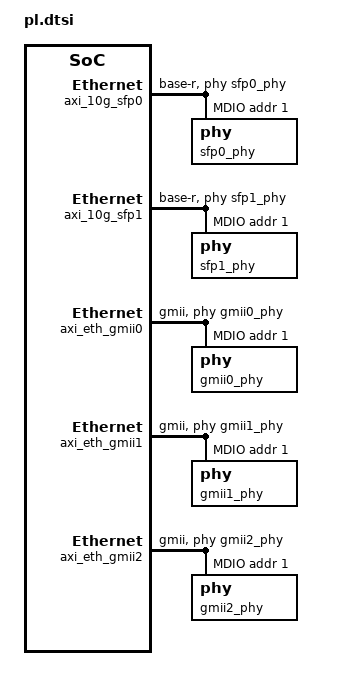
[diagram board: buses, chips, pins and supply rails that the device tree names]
/*
 * CAUTION: This file is automatically generated by Xilinx.
 * Version: XSCT 2019.1
 * Today is: Thu Sep  5 17:37:06 2019
 */


/ {
	amba_pl: amba_pl {
		#address-cells = <1>;
		#size-cells = <1>;
		compatible = "simple-bus";
		ranges ;
		axi_10g_sfp0: ethernet@80000000 {
			axistream-connected = <&sfp0_dma>;
			axistream-control-connected = <&sfp0_dma>;
			clock-frequency = <125000000>;
			clock-names = "dclk", "s_axi_aclk";
			clocks = <&misc_clk_0>, <&misc_clk_0>;
			compatible = "xlnx,axi-10g-ethernet-3.1", "xlnx,ten-gig-eth-mac";
			device_type = "network";
			local-mac-address = [00 0a 35 00 00 00];
			phy-mode = "base-r";
			reg = <0x80000000 0x10000>;
			xlnx = <0x0>;
			xlnx,include-dre ;
			xlnx,rxmem = <0x4000>;
			phy-handle = <&sfp0_phy>;
			axi_10g_sfp0_mdio: mdio {
				#address-cells = <1>;
				#size-cells = <0>;
				sfp0_phy: phy@1 {
					device_type = "ethernet-phy";
					reg = <0x1>;
				};
			};
		};
		misc_clk_0: misc_clk_0 {
			#clock-cells = <0>;
			clock-frequency = <125000000>;
			compatible = "fixed-clock";
		};
		axi_10g_sfp1: ethernet@80010000 {
			axistream-connected = <&sfp1_dma>;
			axistream-control-connected = <&sfp1_dma>;
			clock-frequency = <125000000>;
			clock-names = "dclk", "s_axi_aclk", "txusrclk", "txusrclk2", "coreclk", "qplloutclk", "qplloutrefclk";
			clocks = <&misc_clk_0>, <&misc_clk_0>, <&misc_clk_1>, <&misc_clk_1>, <&misc_clk_2>, <&misc_clk_2>, <&misc_clk_2>;
			compatible = "xlnx,axi-10g-ethernet-3.1", "xlnx,ten-gig-eth-mac";
			device_type = "network";
			local-mac-address = [00 0a 35 00 00 01];
			phy-mode = "base-r";
			reg = <0x80010000 0x10000>;
			xlnx = <0x0>;
			xlnx,include-dre ;
			xlnx,rxmem = <0x4000>;
			phy-handle = <&sfp1_phy>;
			axi_10g_sfp1_mdio: mdio {
				#address-cells = <1>;
				#size-cells = <0>;
				sfp1_phy: phy@1 {
					device_type = "ethernet-phy";
					reg = <0x1>;
				};
			};
		};
		misc_clk_1: misc_clk_1 {
			#clock-cells = <0>;
			clock-frequency = <322265625>;
			compatible = "fixed-clock";
		};
		misc_clk_2: misc_clk_2 {
			#clock-cells = <0>;
			clock-frequency = <156250000>;
			compatible = "fixed-clock";
		};
		axi_eth_gmii0: ethernet@41000000 {
			axistream-connected = <&gmii0_dma>;
			axistream-control-connected = <&gmii0_dma>;
			clock-frequency = <100000000>;
			clock-names = "s_axi_lite_clk", "axis_clk", "gtx_clk";
			clocks = <&clkc 16>, <&clkc 15>, <&misc_clk_0>;
			compatible = "xlnx,axi-ethernet-7.1", "xlnx,axi-ethernet-1.00.a";
			device_type = "network";
			interrupt-names = "interrupt";
			interrupt-parent = <&intc>;
			interrupts = <0 31 4>;
			local-mac-address = [00 0a 35 00 00 02];
			phy-mode = "gmii";
			reg = <0x41000000 0x10000>;
			xlnx = <0x0>;
			xlnx,axiliteclkrate = <0x0>;
			xlnx,axisclkrate = <0x0>;
			xlnx,clockselection = <0x0>;
			xlnx,enableasyncsgmii = <0x0>;
			xlnx,gt-type = <0x0>;
			xlnx,gtinex = <0x0>;
			xlnx,gtlocation = <0x0>;
			xlnx,gtrefclksrc = <0x0>;
			xlnx,include-dre ;
			xlnx,instantiatebitslice0 = <0x0>;
			xlnx,phy-type = <0x1>;
			xlnx,phyaddr = <0x1>;
			xlnx,phyrst-board-interface-dummy-port = <0x0>;
			xlnx,rable = <0x0>;
			xlnx,rxcsum = <0x2>;
			xlnx,rxlane0-placement = <0x0>;
			xlnx,rxlane1-placement = <0x0>;
			xlnx,rxmem = <0x4000>;
			xlnx,rxnibblebitslice0used = <0x0>;
			xlnx,tx-in-upper-nibble = <0x1>;
			xlnx,txcsum = <0x2>;
			xlnx,txlane0-placement = <0x0>;
			xlnx,txlane1-placement = <0x0>;
			phy-handle = <&gmii0_phy>;
			axi_eth_gmii0_mdio: mdio {
				#address-cells = <1>;
				#size-cells = <0>;
				gmii0_phy: phy@1 {
					device_type = "ethernet-phy";
					reg = <0x1>;
				};
			};
		};
		axi_eth_gmii1: ethernet@41010000 {
			axistream-connected = <&gmii1_dma>;
			axistream-control-connected = <&gmii1_dma>;
			clock-frequency = <100000000>;
			clock-names = "s_axi_lite_clk", "axis_clk", "gtx_clk";
			clocks = <&clkc 16>, <&clkc 15>, <&misc_clk_0>;
			compatible = "xlnx,axi-ethernet-7.1", "xlnx,axi-ethernet-1.00.a";
			device_type = "network";
			interrupt-names = "interrupt";
			interrupt-parent = <&intc>;
			interrupts = <0 34 4>;
			local-mac-address = [00 0a 35 00 00 03];
			phy-mode = "gmii";
			reg = <0x41010000 0x10000>;
			xlnx = <0x0>;
			xlnx,axiliteclkrate = <0x0>;
			xlnx,axisclkrate = <0x0>;
			xlnx,clockselection = <0x0>;
			xlnx,enableasyncsgmii = <0x0>;
			xlnx,gt-type = <0x0>;
			xlnx,gtinex = <0x0>;
			xlnx,gtlocation = <0x0>;
			xlnx,gtrefclksrc = <0x0>;
			xlnx,include-dre ;
			xlnx,instantiatebitslice0 = <0x0>;
			xlnx,phy-type = <0x1>;
			xlnx,phyaddr = <0x1>;
			xlnx,phyrst-board-interface-dummy-port = <0x0>;
			xlnx,rable = <0x0>;
			xlnx,rxcsum = <0x2>;
			xlnx,rxlane0-placement = <0x0>;
			xlnx,rxlane1-placement = <0x0>;
			xlnx,rxmem = <0x4000>;
			xlnx,rxnibblebitslice0used = <0x0>;
			xlnx,tx-in-upper-nibble = <0x1>;
			xlnx,txcsum = <0x2>;
			xlnx,txlane0-placement = <0x0>;
			xlnx,txlane1-placement = <0x0>;
			phy-handle = <&gmii1_phy>;
			axi_eth_gmii1_mdio: mdio {
				#address-cells = <1>;
				#size-cells = <0>;
				gmii1_phy: phy@1 {
					device_type = "ethernet-phy";
					reg = <0x1>;
				};
			};
		};
		axi_eth_gmii2: ethernet@41020000 {
			axistream-connected = <&gmii2_dma>;
			axistream-control-connected = <&gmii2_dma>;
			clock-frequency = <100000000>;
			clock-names = "s_axi_lite_clk", "axis_clk", "gtx_clk";
			clocks = <&clkc 16>, <&clkc 15>, <&misc_clk_0>;
			compatible = "xlnx,axi-ethernet-7.1", "xlnx,axi-ethernet-1.00.a";
			device_type = "network";
			interrupt-names = "interrupt";
			interrupt-parent = <&intc>;
			interrupts = <0 52 4>;
			local-mac-address = [00 0a 35 00 00 04];
			phy-mode = "gmii";
			reg = <0x41020000 0x10000>;
			xlnx = <0x0>;
			xlnx,axiliteclkrate = <0x0>;
			xlnx,axisclkrate = <0x0>;
			xlnx,clockselection = <0x0>;
			xlnx,enableasyncsgmii = <0x0>;
			xlnx,gt-type = <0x0>;
			xlnx,gtinex = <0x0>;
			xlnx,gtlocation = <0x0>;
			xlnx,gtrefclksrc = <0x0>;
			xlnx,include-dre ;
			xlnx,instantiatebitslice0 = <0x0>;
			xlnx,phy-type = <0x1>;
			xlnx,phyaddr = <0x1>;
			xlnx,phyrst-board-interface-dummy-port = <0x0>;
			xlnx,rable = <0x0>;
			xlnx,rxcsum = <0x2>;
			xlnx,rxlane0-placement = <0x0>;
			xlnx,rxlane1-placement = <0x0>;
			xlnx,rxmem = <0x4000>;
			xlnx,rxnibblebitslice0used = <0x0>;
			xlnx,tx-in-upper-nibble = <0x1>;
			xlnx,txcsum = <0x2>;
			xlnx,txlane0-placement = <0x0>;
			xlnx,txlane1-placement = <0x0>;
			phy-handle = <&gmii2_phy>;
			axi_eth_gmii2_mdio: mdio {
				#address-cells = <1>;
				#size-cells = <0>;
				gmii2_phy: phy@1 {
					device_type = "ethernet-phy";
					reg = <0x1>;
				};
			};
		};
		gmii0_dma: dma@40400000 {
			#dma-cells = <1>;
			axistream-connected = <&axi_eth_gmii0>;
			axistream-control-connected = <&axi_eth_gmii0>;
			clock-names = "s_axi_lite_aclk", "m_axi_sg_aclk", "m_axi_mm2s_aclk", "m_axi_s2mm_aclk";
			clocks = <&clkc 16>, <&clkc 15>, <&clkc 15>, <&clkc 15>;
			compatible = "xlnx,eth-dma";
			interrupt-names = "mm2s_introut", "s2mm_introut";
			interrupt-parent = <&intc>;
			interrupts = <0 30 4 0 29 4>;
			reg = <0x40400000 0x10000>;
			xlnx,include-dre ;
		};
		gmii1_dma: dma@40410000 {
			#dma-cells = <1>;
			axistream-connected = <&axi_eth_gmii1>;
			axistream-control-connected = <&axi_eth_gmii1>;
			clock-names = "s_axi_lite_aclk", "m_axi_sg_aclk", "m_axi_mm2s_aclk", "m_axi_s2mm_aclk";
			clocks = <&clkc 16>, <&clkc 15>, <&clkc 15>, <&clkc 15>;
			compatible = "xlnx,eth-dma";
			interrupt-names = "mm2s_introut", "s2mm_introut";
			interrupt-parent = <&intc>;
			interrupts = <0 33 4 0 32 4>;
			reg = <0x40410000 0x10000>;
			xlnx,include-dre ;
		};
		gmii2_dma: dma@40420000 {
			#dma-cells = <1>;
			axistream-connected = <&axi_eth_gmii2>;
			axistream-control-connected = <&axi_eth_gmii2>;
			clock-names = "s_axi_lite_aclk", "m_axi_sg_aclk", "m_axi_mm2s_aclk", "m_axi_s2mm_aclk";
			clocks = <&clkc 16>, <&clkc 15>, <&clkc 15>, <&clkc 15>;
			compatible = "xlnx,eth-dma";
			interrupt-names = "mm2s_introut", "s2mm_introut";
			interrupt-parent = <&intc>;
			interrupts = <0 36 4 0 35 4>;
			reg = <0x40420000 0x10000>;
			xlnx,include-dre ;
		};
		sfp0_dma: dma@80400000 {
			#dma-cells = <1>;
			axistream-connected = <&axi_10g_sfp0>;
			axistream-control-connected = <&axi_10g_sfp0>;
			clock-names = "s_axi_lite_aclk", "m_axi_sg_aclk", "m_axi_mm2s_aclk", "m_axi_s2mm_aclk";
			clocks = <&misc_clk_0>, <&misc_clk_2>, <&misc_clk_2>, <&misc_clk_2>;
			compatible = "xlnx,eth-dma";
			interrupt-names = "mm2s_introut", "s2mm_introut";
			interrupt-parent = <&intc>;
			interrupts = <0 54 4 0 53 4>;
			reg = <0x80400000 0x10000>;
			xlnx,include-dre ;
		};
		sfp1_dma: dma@80410000 {
			#dma-cells = <1>;
			axistream-connected = <&axi_10g_sfp1>;
			axistream-control-connected = <&axi_10g_sfp1>;
			clock-names = "s_axi_lite_aclk", "m_axi_sg_aclk", "m_axi_mm2s_aclk", "m_axi_s2mm_aclk";
			clocks = <&misc_clk_0>, <&misc_clk_2>, <&misc_clk_2>, <&misc_clk_2>;
			compatible = "xlnx,eth-dma";
			interrupt-names = "mm2s_introut", "s2mm_introut";
			interrupt-parent = <&intc>;
			interrupts = <0 56 4 0 55 4>;
			reg = <0x80410000 0x10000>;
			xlnx,include-dre ;
		};
	};
};
